# mlbss_MLBDIM_CFG_02F82000h register map
Vendor: Texas Instruments
Peripheral module from a debugger description file (folder AM275x).
Registers are 32-bit, read-write, reset 0x0 unless marked. A register's access mark holds for its fields unless they carry their own. Offsets are as the file gives them; lines under a group give offsets from that group; [hi:lo] are bit positions; {n}, {i} and the like mark numbered series; 'fields as' and 'values as' point back to an identical list; <NAME> marks a mode.

## mlbdim_cfg
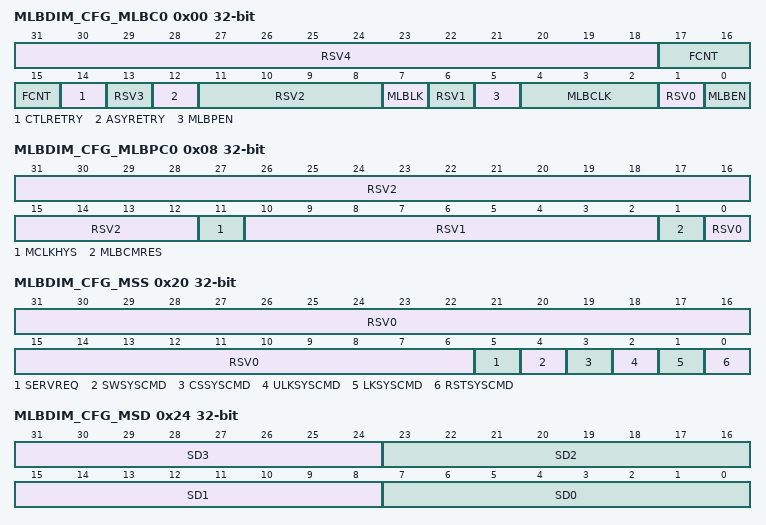
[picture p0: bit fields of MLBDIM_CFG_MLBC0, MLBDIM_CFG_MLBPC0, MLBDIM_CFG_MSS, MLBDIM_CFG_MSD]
0x00 MLBDIM_CFG_MLBC0 access per field — See reference [R1].
  [31:18] RSV4 ro — Reserved Reset Source: prst_n
  [17:15] FCNT rw — The number of frames per sub-buffer for synchronous channels. 000 - 1 frame per sub-buffer (Operation is the same as Standard mode) 001 - 2 frames per sub-buffer 010 - 4 frames per sub-buffer 011 - 8 frames per sub-buffer 100 - 16 frames per sub-buffer 101 - 32 frames per sub-buffer 110 - 64 frames per sub-buffer 111 - Reserved Reset Source: prst_n
  [14] CTLRETRY rw — Control Tx packet retry. When set, a control packet that is flagged with a Break or ProtocolError by the receiver is retransmitted. When cleared, a control packet that is flagged with a Break or ProtocolError by the receiver is skipped. Reset Source: prst_n
  [13] RSV3 ro — Reserved Reset Source: prst_n
  [12] ASYRETRY rw — Asynchronous Tx packet retry. When set, an asynchronous packet that is flagged with a Break or ProtocolError by the receiver is retransmitted. When cleared, an asynchronous packet that is flagged with a Break or ProtocolError by the receiver is skipped. Reset Source: prst_n
  [11:8] RSV2 ro — Reserved Reset Source: prst_n
  [7] MLBLK ro — MediaLB lock status. When set, indicates that the MediaLB block is synchronized to the incoming MediaLB frame. If MLBLK is clear (unlocked), MLBLK is set after FRAMESYNC is detected at the same position for three consecutive frames. If MLBLK is set (locked), MLBLK is cleared after not receiving FRAMESYNC at the expected time for two consecutive frames. While MLBLK is set, FRAMESYNC patterns occurring at locations other than the expected one are ignored. (read-only) Reset Source: prst_n
  [6] RSV1 ro — Reserved Reset Source: prst_n
  [5] MLBPEN rw — MediaLB 6-pin enable. 0 - MediaLB 3-pin interface enabled 1 - MediaLB 6-pin interface enabled Reset Source: prst_n
  [4:2] MLBCLK rw — MediaLB clock speed select. 000 - 256xFs (for MLBPEN = 0) 001 - 512xFs (for MLBPEN = 0) 010 - 1024xFs (for MLBPEN = 0) 011 - 2048xFs (for MLBPEN = 1) 100 - 3072xFs (for MLBPEN = 1) 101 - 4096xFs (for MLBPEN = 1) 110 - 6144xFs (for MLBPEN = 1) 111 - 8192xFs (for MLBPEN = 1) Reset Source: prst_n
  [1] RSV0 ro — Reserved Reset Source: prst_n
  [0] MLBEN rw — MediaLB enable. When set, MediaLB clock, signal, and data are received and transmitted on the appropriate MediaLB pins. Reset Source: prst_n
0x08 MLBDIM_CFG_MLBPC0 access per field — See reference [R1].
  [31:12] RSV2 ro — Reserved Reset Source: prst_n
  [11] MCLKHYS rw — MediaLB 6-pin clock hystersis enable. When set, enables hysteresis on the MediaLB clock. This value is driven on mlb_clk_hys_enable output pin and has no internal function. Reset Source: prst_n
  [10:2] RSV1 ro — Reserved Reset Source: prst_n
  [1] MLBCMRES rw — MediaLB 6-pin common mode resistor enable. No longer used Reset Source: prst_n
  [0] RSV0 ro — Reserved Reset Source: prst_n
0x0C MLBDIM_CFG_MS0 access not given — See reference [R1].
  [31:0] MCS — MediaLB channel status. Indicates the channel status for MediaLB channels 31 to 0. Channel status bits are set by hardware and cleared by software. Status is only set if the appropriate bits in the MIEN register are set. Reset Source: prst_n (access R/W0TC)
0x14 MLBDIM_CFG_MS1 access not given — See reference [R1].
  [31:0] MCS — MediaLB channel status. Indicates the channel status for MediaLB channels 63 to 32. Channel status bits are set by hardware and cleared by software. Status is only set if the appropriate bits in the MIEN register are set. Reset Source: prst_n (access R/W0TC)
0x20 MLBDIM_CFG_MSS access not given — See reference [R1].
  [31:6] RSV0 ro — Reserved Reset Source: prst_n
  [5] SERVREQ rw — Service request enabled. When set, the MediaLB block responds with a 'device present, request service' system response if a matching channel scan system command is detected. When cleared, the MediaLB block responds with a 'device present' system response. Reset Source: prst_n
  [4] SWSYSCMD — Sowftware system command detected (in the system quadlet). Set by hardware, cleared by software. Data is stored in the MSD register for this command. Reset Source: prst_n (access R/W0TC)
  [3] CSSYSCMD — Channel scan system command detected (in the system quadlet). Set by hardware, cleared by software. If the node address specified in Data quadlet matches the value in MLBC1.NDA, the device responds either 'device present' or 'device present, request service' system response in the next system quadlet. Reset Source: prst_n (access R/W0TC)
  [2] ULKSYSCMD — Network unlock system command detected (in the system quadlet). Set by hardware, cleared by software. Reset Source: prst_n (access R/W0TC)
  [1] LKSYSCMD — Network lock system command detected (in the system quadlet). Set by hardware, cleared by software. Reset Source: prst_n (access R/W0TC)
  [0] RSTSYSCMD — Reset system command detected (in the system quadlet). Set by hardware, cleared by software. Reset Source: prst_n (access R/W0TC)
0x24 MLBDIM_CFG_MSD ro — See reference [R1].
  [31:24] SD3 — System data (byte 3) - MSB. Updated with MediaLB Data[31:24] when a MediaLB software system command is received in the system quadlet. If MSS.SWSYSCMD is already set, then SD3 is not updated. (read-only) Reset Source: prst_n
  [23:16] SD2 — System data (byte 2). Updated with MediaLB Data[23:16] when a MediaLB software system command is received in the system quadlet. If MSS.SWSYSCMD is already set, then SD2 is not updated. (readonly) Reset Source: prst_n
  [15:8] SD1 — System data (byte 1). Updated with MediaLB Data[15:8] when a MediaLB software system command is received in the system quadlet. If MSS.SWSYSCMD is already set, then SD1 is not updated. (read-only) Reset Source: prst_n
  [7:0] SD0 — System data (byte 0) - LSB. Updated with MediaLB Data[7:0] when a MediaLB software system command is received in the system quadlet. If MSS.SWSYSCMD is already set, then SD0 is not updated. (readonly) Reset Source: prst_n
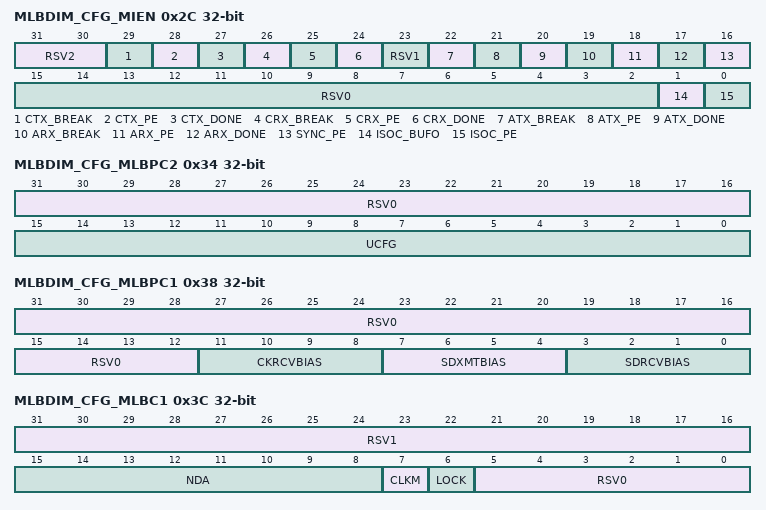
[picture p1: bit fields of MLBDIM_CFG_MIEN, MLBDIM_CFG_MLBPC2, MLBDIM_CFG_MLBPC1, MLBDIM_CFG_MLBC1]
0x2C MLBDIM_CFG_MIEN — See reference [R1].
  [31:30] RSV2 — Reserved (write default value) Reset Source: prst_n
  [29] CTX_BREAK — Control Tx break enable. When set, a ReceiverBreak response received from the receiver on a control Tx channel causes the appropriate channel bit in the MS0 or MS1 registers to be set. Reset Source: prst_n
  [28] CTX_PE — Control Tx protocol error enable. When set, a ProtocolError generated by the receiver on a control Tx channel causes the appropriate channel bit in the MS0 or MS1 registers to be set. Reset Source: prst_n
  [27] CTX_DONE — Control Tx packet done enable. When set, a packet transmitted with no errors on a control Tx channel causes the appropriate channel bit in the MS0 or MS1 registers to be set. Reset Source: prst_n
  [26] CRX_BREAK — Control Rx break enable. When set, a ControlBreak command received from the transmitter on a control Rx channel causes the appropriate channel bit in the MS0 or MS1 registers to be set. Reset Source: prst_n
  [25] CRX_PE — Control Rx protocol error enable. When set, a packet received with no errors on a control Rx channel causes the appropriate channel bit in the MS0 or MS1 registers to be set. Reset Source: prst_n
  [24] CRX_DONE — Control Rx packet done enable. When set, a packet received with no errors on a control Rx channel causes the appropriate channel bit in the MS0 or MS1 registers to be set. Reset Source: prst_n
  [23] RSV1 — Reserved (write default value) Reset Source: prst_n
  [22] ATX_BREAK — Asynchronous Tx break enable. When set, a ReceiverBreak response received from the receiver on an asynchronous Tx channel causes the appropriate channel bit in the MS0 or MS1 registers to be set. Reset Source: prst_n
  [21] ATX_PE — Asynchronous Tx protocol error enable. When set, a ProtocolError generated by the receiver on an asynchronous Tx channel causes the appropriate channel bit in the MS0 or MS1 registers to be set. Reset Source: prst_n
  [20] ATX_DONE — Asynchronous Tx packet done enable. When set, a packet transmitted with no errors on an asynchronous Tx channel causes the appropriate channel bit in the MS0 or MS1 registers to be set. Reset Source: prst_n
  [19] ARX_BREAK — Asynchronous Rx break enable. When set, a AsyncBreak command received from the transmitter on an asynchronous Rx channel causes the appropriate channel bit in the MS0 or MS1 registers to be set. Reset Source: prst_n
  [18] ARX_PE — Asynchronous Rx protocol enable. When set, a ProtocolError detected on an asynchronous Rx channel causes the appropriate channel bit in the MS0 or MS1 registers to be set. Reset Source: prst_n
  [17] ARX_DONE — Asynchronous Rx packet done enable. When set, a packet received with no errors on an asynchronous Rx channel causes the appropriate channel bit in the MS0 or MS1 registers to be set. Reset Source: prst_n
  [16] SYNC_PE — Synchronous protocol error enable. When set, a ProtocolError detected on a synchronous Rx channel causes the appropriate channel bit in the MS0 or MS1 registers to be set. Reset Source: prst_n
  [15:2] RSV0 — Reserved (write default value) Reset Source: prst_n
  [1] ISOC_BUFO — Isochronous Rx buffer overflow enable. When set, a buffer overflow on an isochronous Rx channel causes the appropriate channel bit in the MS0 or MS1 registers to be set. This occurs only when isochronous flow control is disabled. Reset Source: prst_n
  [0] ISOC_PE — Isochronous Rx protocol error enable. When set, a ProtocolError detected on an isochronous Rx channel causes the appropriate channel bit in the MS0 or MS1 registers to be set. Reset Source: prst_n
0x34 MLBDIM_CFG_MLBPC2 access per field — See reference [R1].
  [31:16] RSV0 ro — Reserved Reset Source: prst_n
  [15:0] UCFG rw — User Defined Configuration Register. This 16-bit register is output to the MediaLB physical interface (mlbp_user_cfg[15:0]) for additional control of external modules (i.e MediaLB 6-pin Analog module). Reset Source: prst_n
0x38 MLBDIM_CFG_MLBPC1 access per field — See reference [R1].
  [31:12] RSV0 ro — Reserved Reset Source: prst_n
  [11:8] CKRCVBIAS rw — Clock receiver bias control (for MediaLB 6-pin interface). This value is driven on mlb_clk_rx_bias_ctl[3:0] output pin and has no internal function. Reset Source: prst_n
  [7:4] SDXMTBIAS rw — Signal/Data transmitter bias control (for MediaLB 6-pin interface). This value is driven on mlb_sig_data_tx_bias_ctl[3:0] output pin and has no internal function. Reset Source: prst_n
  [3:0] SDRCVBIAS rw — Signal/Data reciever bias control (for MediaLB 6-pin interface). This value is driven on mlb_sig_data_rx_bias_ctl[3:0] output pin and has no internal function. Reset Source: prst_n
0x3C MLBDIM_CFG_MLBC1 access not given — See reference [R1].
  [31:16] RSV1 ro — Reserved Reset Source: prst_n
  [15:8] NDA rw — Node device address. Used for system commands directed to individual MediaLB nodes. Reset Source: prst_n
  [7] CLKM — MediaLB clock missing status. Set when MediaLB clock is not toggling at the pin; cleared by software. Reset Source: prst_n (access R/W0TC)
  [6] LOCK — MediaLB lock error status. Set when MediaLB is unlocked; cleared by software. Reset Source: prst_n (access R/W0TC)
  [5:0] RSV0 ro — Reserved Reset Source: prst_n
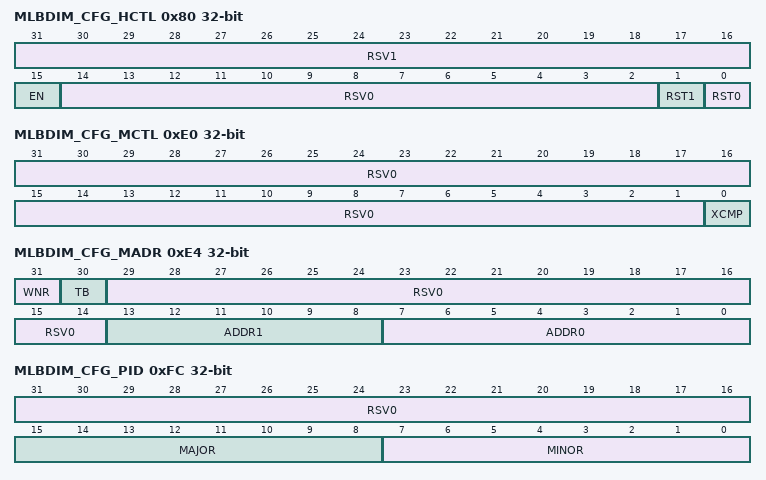
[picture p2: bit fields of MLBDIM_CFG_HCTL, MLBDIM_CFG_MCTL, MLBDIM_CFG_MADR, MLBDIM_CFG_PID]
0x80 MLBDIM_CFG_HCTL — See reference [R1].
  [31:16] RSV1 — Reserved (write default value) Reset Source: prst_n
  [15] EN — HBI enable: 1 = enabled, 0 = disabled Reset Source: prst_n
  [14:2] RSV0 — Reserved (write default value) Reset Source: prst_n
  [1] RST1 — AGU1 software reset: 1 = reset active, 0 = reset inactive Reset Source: prst_n
  [0] RST0 — AGU0 software reset: 1 = reset active, 0 = reset inactive Reset Source: prst_n
0x88 MLBDIM_CFG_HCMR0 — See reference [R1].
  [31:0] CHM — Bitwise channel mask bit [31:0]: 0 = masked, 1 = unmasked Reset Source: prst_n
0x8C MLBDIM_CFG_HCMR1 — See reference [R1].
  [31:0] CHM — Bitwise channel mask bit [63:32]: 0 = masked, 1 = unmasked Reset Source: prst_n
0x90 MLBDIM_CFG_HCER0 access not given — See reference [R1].
  [31:0] CERR — Bitwise channel error bit[31:0] Reset Source: prst_n (access R/W0TC)
0x94 MLBDIM_CFG_HCER1 access not given — See reference [R1].
  [31:0] CERR — Bitwise channel error bit[63:32] Reset Source: prst_n (access R/W0TC)
0x98 MLBDIM_CFG_HCBR0 ro — See reference [R1].
  [31:0] CHB — Bitwise channel busy bit[31:0]: 0 = idle, 1 = busy Reset Source: prst_n
0x9C MLBDIM_CFG_HCBR1 ro — See reference [R1].
  [31:0] CHB — Bitwise channel busy bit[63:32]: 0 = idle, 1 = busy Reset Source: prst_n
0xC0 MLBDIM_CFG_MDAT0 — See reference [R1].
  [31:0] DATA — CTR data - bits[31:0] of 128-bit entry or DBR data - bits[7:0] of 8-bit entry Reset Source: prst_n
{0xC0+4i} MLBDIM_CFG_MDAT{i} (i=1..3) — See reference [R1].
  [31:0] DATA — CTR data - bits[{32i+31}:{32i}] of 128-bit entry Reset Source: prst_n
{0xD0+4i} MLBDIM_CFG_MDWE{i} (i=0..3) — See reference [R1].
  [31:0] MASK — Bitwise write enable for CTR data - bits[{32i+31}:{32i}] (0 = disabled, 1 = enabled) Reset Source: prst_n
0xE0 MLBDIM_CFG_MCTL access not given — See reference [R1].
  [31:1] RSV0 rw — Reserved (write default value) Reset Source: prst_n
  [0] XCMP — Transfer complete (write 0 to clear) Reset Source: prst_n (access R/W0TC)
0xE4 MLBDIM_CFG_MADR — See reference [R1].
  [31] WNR — Write-Not-Read selection (0 = read, 1 = write) Reset Source: prst_n
  [30] TB — Target location bit (0 = selects CTR, 1 = selects DBR) Reset Source: prst_n
  [29:14] RSV0 — Reserved (write default value) Reset Source: prst_n
  [13:8] ADDR1 — DBR address of 8-bit entry - bits[13:8] Reset Source: prst_n
  [7:0] ADDR0 — CTR address of 128-bit entry or DBR address of 8-bit entry - bits[7:0] Reset Source: prst_n
0xFC MLBDIM_CFG_PID ro — Microchip 3rd party MediaLB Device Interface Macro 2 soft IP core revision register.
  [31:16] RSV0 — Reserved Reset Source: prst_n
  [15:8] MAJOR — Major revision Reset Source: prst_n
  [7:0] MINOR — Minor revision Reset Source: prst_n
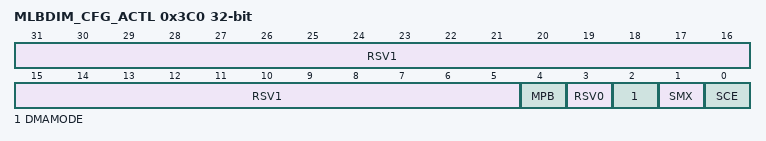
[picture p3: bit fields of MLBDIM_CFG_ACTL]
0x3C0 MLBDIM_CFG_ACTL — See reference [R1].
  [31:5] RSV1 — Reserved (write default value) Reset Source: prst_n
  [4] MPB — Packet buffering mode: 0 = single-packet mode 1 = multiple-packet mode Reset Source: prst_n
  [3] RSV0 — Reserved (write default value) Reset Source: prst_n
  [2] DMAMODE — DMA Mode: 0 = DMA Mode 0 1 = DMA Mode 1 Reset Source: prst_n
  [1] SMX — AHB interrupt mux enable: 0 = ACSR0 generates an interrupt on ahb_int[0]; ACSR1 generates an interrupt on ahb_int[1] 1 = ACSR0 and ACSR1 generate an interrupts on ahb_int[0] only Reset Source: prst_n
  [0] SCE — Software clear enable: 0 = Hardware clears interrupt after a ACSRn register read 1 = Software clears interrupt Reset Source: prst_n
0x3D0 MLBDIM_CFG_ACSR0 access not given — See reference [R1].
  [31:0] CHS — Interrupt status for logical channels 31 to 0: 0 = None 1 = Interrupt Reset Source: prst_n (access R/W1TC)
0x3D4 MLBDIM_CFG_ACSR1 access not given — See reference [R1].
  [31:0] CHS — Interrupt status for logical channels 63 to 32: 0 = None 1 = Interrupt Reset Source: prst_n (access R/W1TC)
0x3D8 MLBDIM_CFG_ACMR0 — See reference [R1].
  [31:0] CHM — Bitwise channel mask bit[31:0]: 0 = Masked 1 = Unmasked Reset Source: prst_n
0x3DC MLBDIM_CFG_ACMR1 — See reference [R1].
  [31:0] CHM — Bitwise channel mask bit[63:32]: 0 = Masked 1 = Unmasked Reset Source: prst_n
